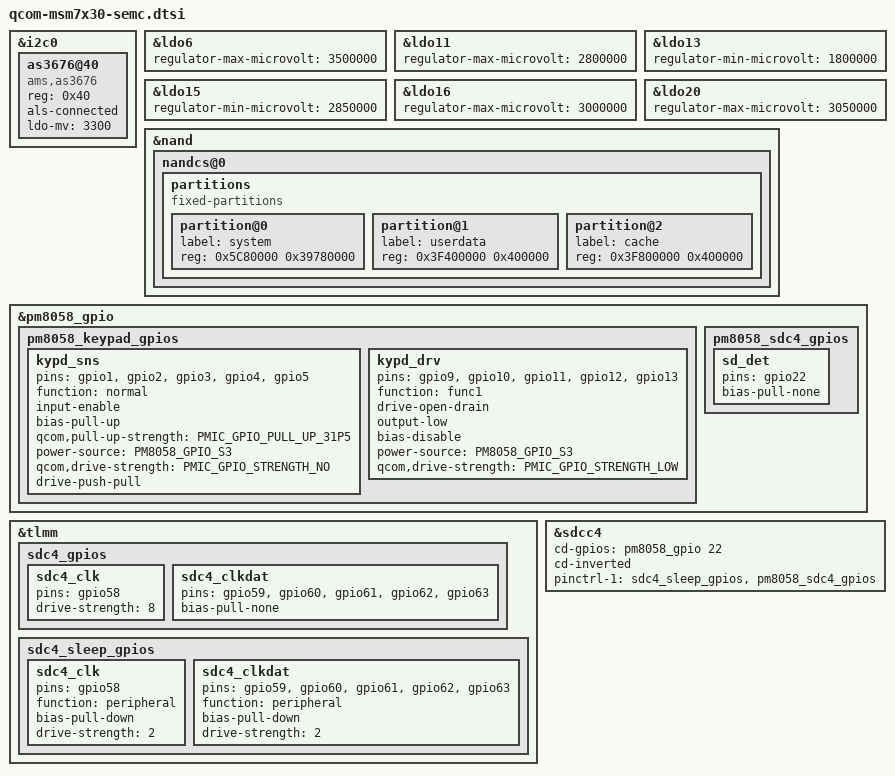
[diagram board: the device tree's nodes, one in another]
#include "qcom-msm7x30.dtsi"

&i2c0 {
	as3676@40 {
		compatible = "ams,as3676";
		reg = <0x40>;

		als-connected;
		ldo-mv = <3300>;
	};
};

&ldo6 {
	regulator-max-microvolt = <3500000>;
};

&ldo11 {
	regulator-max-microvolt = <2800000>;
};

&ldo13 {
	regulator-min-microvolt = <1800000>;
};

&ldo15 {
	regulator-min-microvolt = <2850000>;
};

&ldo16 {
	regulator-max-microvolt = <3000000>;
};

&ldo20 {
	regulator-max-microvolt = <3050000>;
};

&nand {
	status = "ok";
	nandcs@0 {
		partitions {
			compatible = "fixed-partitions";
			#address-cells = <1>;
			#size-cells = <1>;

			partition@0 {
				label= "system";
				reg = <0x5C80000 0x39780000>;
			};
			partition@1 {
				label= "userdata";
				reg = <0x3F400000 0x400000>;
			};
			partition@2 {
				label= "cache";
				reg = <0x3F800000 0x400000>;
			};
		};
	};

};

&pm8058_gpio {
	pm8058_keypad_gpios: pm8058_keypad_gpios {
		kypd_sns {
			pins = "gpio1", "gpio2", "gpio3", "gpio4", "gpio5";
			function = "normal";
			input-enable;
			bias-pull-up;
			qcom,pull-up-strength = <PMIC_GPIO_PULL_UP_31P5>;
			power-source = <PM8058_GPIO_S3>;
			qcom,drive-strength = <PMIC_GPIO_STRENGTH_NO>;
			drive-push-pull;
		};

		kypd_drv {
			pins = "gpio9", "gpio10", "gpio11", "gpio12", "gpio13";
			function = "func1";
			drive-open-drain;
			output-low;
			bias-disable;
			power-source = <PM8058_GPIO_S3>;
			qcom,drive-strength = <PMIC_GPIO_STRENGTH_LOW>;
		};
	};

	pm8058_sdc4_gpios: pm8058_sdc4_gpios {
		sd_det {
			pins = "gpio22";
			bias-pull-none;
			/delete-property/ qcom,pull-up-strength;
		};
	};
};

&tlmm {
	sdc4_gpios: sdc4_gpios {
		sdc4_clk {
			pins = "gpio58";
			drive-strength = <8>;
		};

		sdc4_clkdat {
			pins = "gpio59", "gpio60", "gpio61", "gpio62", "gpio63";
			bias-pull-none;
		};
	};

	sdc4_sleep_gpios: sdc4_sleep_gpios {
		sdc4_clk {
			pins = "gpio58";
			function = "peripheral";
			bias-pull-down;
			drive-strength = <2>;
		};

		sdc4_clkdat {
			pins = "gpio59", "gpio60", "gpio61", "gpio62", "gpio63";
			function = "peripheral";
			bias-pull-down;
			drive-strength = <2>;
		};
	};
};

/* External micro SD card */
&sdcc4 {
	status = "ok";
	cd-gpios = <&pm8058_gpio 22 0>;
	cd-inverted;

	pinctrl-names	= "default", "sleep";
	pinctrl-1	= <&sdc4_sleep_gpios>,
			  <&pm8058_sdc4_gpios>;
};
